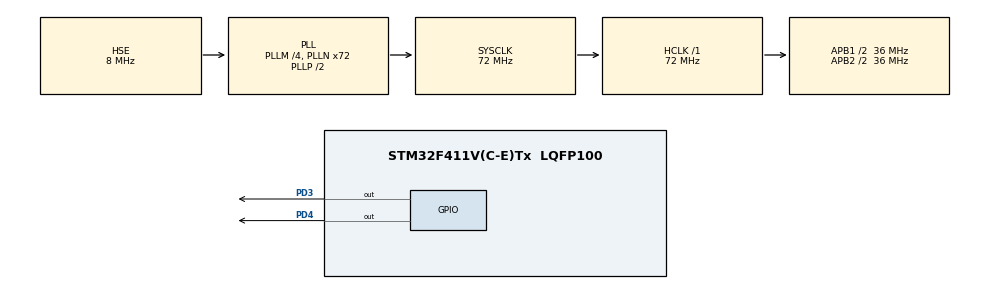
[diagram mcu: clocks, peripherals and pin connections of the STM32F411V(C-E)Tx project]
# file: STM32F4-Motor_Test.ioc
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Mcu.Family=STM32F4
Mcu.Name=STM32F411V(C-E)Tx
Mcu.Package=LQFP100
NVIC.PriorityGroup=NVIC_PRIORITYGROUP_0
PD3.Signal=GPIO_Output
PD4.Signal=GPIO_Output
PH0\ -\ OSC_IN.Mode=HSE-External-Oscillator
PH0\ -\ OSC_IN.Signal=RCC_OSC_IN
PH1\ -\ OSC_OUT.Mode=HSE-External-Oscillator
PH1\ -\ OSC_OUT.Signal=RCC_OSC_OUT
ProjectManager.HeapSize=0x200
ProjectManager.StackSize=0x400
ProjectManager.TargetToolchain=STM32CubeIDE
RCC.48MHZClocksFreq_Value=18000000
RCC.AHBFreq_Value=72000000
RCC.APB1CLKDivider=RCC_HCLK_DIV2
RCC.APB1Freq_Value=36000000
RCC.APB1TimFreq_Value=72000000
RCC.APB2CLKDivider=RCC_HCLK_DIV2
RCC.APB2Freq_Value=36000000
RCC.APB2TimFreq_Value=72000000
RCC.CortexFreq_Value=72000000
RCC.HCLKFreq_Value=72000000
RCC.HSE_VALUE=8000000
RCC.HSI_VALUE=16000000
RCC.LSE_VALUE=32768
RCC.PLLI2SM=5
RCC.PLLI2SN=200
RCC.PLLM=4
RCC.PLLN=72
RCC.PLLQ=8
RCC.PLLSourceVirtual=RCC_PLLSOURCE_HSE
RCC.SYSCLKFreq_VALUE=72000000
RCC.SYSCLKSource=RCC_SYSCLKSOURCE_PLLCLK
RCC.VCOOutputFreq_Value=144000000
TIM1.Prescaler=71
VP_TIM1_VS_ClockSourceINT.Mode=Internal
board=STM32F411E-DISCO

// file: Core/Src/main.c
/* USER CODE BEGIN Header */
/**
  ******************************************************************************
  * @file           : main.c
  * @brief          : Main program body
  ******************************************************************************
  * @attention
  *
  * Copyright (c) 2023 STMicroelectronics.
  * All rights reserved.
  *
  * This software is licensed under terms that can be found in the LICENSE file
  * in the root directory of this software component.
  * If no LICENSE file comes with this software, it is provided AS-IS.
  *
  ******************************************************************************
  */
/* USER CODE END Header */
#include "main.h"
#include "tim.h"
#include "gpio.h"

void SystemClock_Config(void);

/* USER CODE BEGIN 0 */
#define DIR_PIN GPIO_PIN_4
#define DIR_PORT GPIOD
#define STEP_PIN GPIO_PIN_3
#define STEP_PORT GPIOD

void microDelay (uint16_t delay)
{
  __HAL_TIM_SET_COUNTER(&htim1, 0);
  while (__HAL_TIM_GET_COUNTER(&htim1) < delay);
}

void step (int steps, uint8_t direction, uint16_t delay)
{
  int x;
  if (direction == 0)
    HAL_GPIO_WritePin(DIR_PORT, DIR_PIN, GPIO_PIN_SET);
  else
    HAL_GPIO_WritePin(DIR_PORT, DIR_PIN, GPIO_PIN_RESET);
  for(x=0; x<steps; x=x+1)
  {
    HAL_GPIO_WritePin(STEP_PORT, STEP_PIN, GPIO_PIN_SET);
    microDelay(delay);
    HAL_GPIO_WritePin(STEP_PORT, STEP_PIN, GPIO_PIN_RESET);
    microDelay(delay);
  }
}

/* USER CODE END 0 */

int main(void)
{

  /* MCU Configuration--------------------------------------------------------*/

  /* Reset of all peripherals, Initializes the Flash interface and the Systick. */
  HAL_Init();

  /* Configure the system clock */
  SystemClock_Config();

  /* Initialize all configured peripherals */
  MX_GPIO_Init();
  MX_TIM1_Init();
  /* USER CODE BEGIN 2 */
  HAL_TIM_Base_Start(&htim1);
  /* USER CODE END 2 */

  /* Infinite loop */
  /* USER CODE BEGIN WHILE */
  while (1)
    {
      int y;
      for(y=0; y<8; y=y+1) // 8 times
      {
        step(50, 0, 1000); // 25 steps (45 degrees) CCV
        HAL_Delay(500);
      }
      step(800, 1, 1000); // 800 steps (4 revolutions ) CV
      HAL_Delay(1000);
      /* USER CODE END WHILE */

    }
}

void SystemClock_Config(void)
{
  RCC_OscInitTypeDef RCC_OscInitStruct = {0};
  RCC_ClkInitTypeDef RCC_ClkInitStruct = {0};

  /** Configure the main internal regulator output voltage
  */
  __HAL_RCC_PWR_CLK_ENABLE();
  __HAL_PWR_VOLTAGESCALING_CONFIG(PWR_REGULATOR_VOLTAGE_SCALE1);

  /** Initializes the RCC Oscillators according to the specified parameters
  * in the RCC_OscInitTypeDef structure.
  */
  RCC_OscInitStruct.OscillatorType = RCC_OSCILLATORTYPE_HSE;
  RCC_OscInitStruct.HSEState = RCC_HSE_ON;
  RCC_OscInitStruct.PLL.PLLState = RCC_PLL_ON;
  RCC_OscInitStruct.PLL.PLLSource = RCC_PLLSOURCE_HSE;
  RCC_OscInitStruct.PLL.PLLM = 4;
  RCC_OscInitStruct.PLL.PLLN = 72;
  RCC_OscInitStruct.PLL.PLLP = RCC_PLLP_DIV2;
  RCC_OscInitStruct.PLL.PLLQ = 8;
  if (HAL_RCC_OscConfig(&RCC_OscInitStruct) != HAL_OK)
  {
    Error_Handler();
  }

  /** Initializes the CPU, AHB and APB buses clocks
  */
  RCC_ClkInitStruct.ClockType = RCC_CLOCKTYPE_HCLK|RCC_CLOCKTYPE_SYSCLK
                              |RCC_CLOCKTYPE_PCLK1|RCC_CLOCKTYPE_PCLK2;
  RCC_ClkInitStruct.SYSCLKSource = RCC_SYSCLKSOURCE_PLLCLK;
  RCC_ClkInitStruct.AHBCLKDivider = RCC_SYSCLK_DIV1;
  RCC_ClkInitStruct.APB1CLKDivider = RCC_HCLK_DIV2;
  RCC_ClkInitStruct.APB2CLKDivider = RCC_HCLK_DIV2;

  if (HAL_RCC_ClockConfig(&RCC_ClkInitStruct, FLASH_LATENCY_2) != HAL_OK)
  {
    Error_Handler();
  }
}

void Error_Handler(void)
{
  __disable_irq();
  while (1)
  {
  }
}
